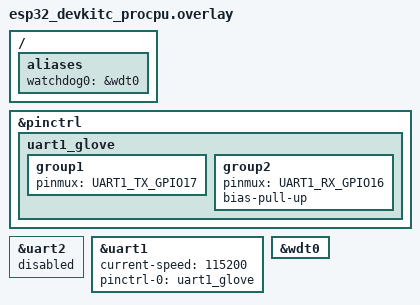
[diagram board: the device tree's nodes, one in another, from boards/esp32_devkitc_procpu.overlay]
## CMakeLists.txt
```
# SPDX-License-Identifier: Apache-2.0
# GloveAssist — ESP32 Application CMakeLists.txt

cmake_minimum_required(VERSION 3.20.0)

find_package(Zephyr REQUIRED HINTS $ENV{ZEPHYR_BASE})
project(gloveassist_esp32 LANGUAGES C)

# Shared + target-specific headers
target_include_directories(app PRIVATE
    ${CMAKE_CURRENT_SOURCE_DIR}/../common/include
    ${CMAKE_CURRENT_SOURCE_DIR}/include
)

# Common shared sources (protocol, CRC)
target_sources(app PRIVATE
    ../common/src/frame_protocol.c
)

# ESP32-specific application sources
target_sources(app PRIVATE
    src/main.c
    src/uart_comm.c
    src/comms_ble.c
    src/sensor_filter.c
    src/gesture_classify.c
)

if(CONFIG_NETWORKING AND CONFIG_MQTT_LIB)
    target_sources(app PRIVATE src/wifi_mqtt.c)
endif()
```

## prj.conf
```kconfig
# GloveAssist — ESP32 Kconfig
# Target: ESP32-WROOM DevKit — BLE gateway + UART receiver

# ---- Kernel ----
CONFIG_MULTITHREADING=y
CONFIG_MAIN_STACK_SIZE=2048
CONFIG_SYSTEM_WORKQUEUE_STACK_SIZE=2048
CONFIG_IDLE_STACK_SIZE=1024
CONFIG_ISR_STACK_SIZE=2048

# ---- GPIO ----
CONFIG_GPIO=y

# ---- UART (inter-MCU communication with STM32 via UART2) ----
CONFIG_UART_INTERRUPT_DRIVEN=y

# ---- Display ----
# OLED is connected to STM32 over I2C2. ESP32 does not drive a display.

# ---- Bluetooth (NUS service) ----
CONFIG_BT=y
CONFIG_BT_PERIPHERAL=y
CONFIG_BT_GATT_DYNAMIC_DB=y
CONFIG_BT_DEVICE_NAME="GloveAssist"
CONFIG_BT_MAX_CONN=1
# Keep the hardware validation image simple: no pairing required for nRF Connect/app tests.
# The encrypted profile can be re-enabled after the end-to-end flow is stable.
CONFIG_BT_SMP=n

# ---- PWM (motor + buzzer, optional on ESP32) — disabled for initial build ----
# CONFIG_PWM=y

# ---- Watchdog ----
CONFIG_WATCHDOG=y

# ---- Logging ----
CONFIG_LOG=y
CONFIG_LOG_DEFAULT_LEVEL=4
CONFIG_LOG_BACKEND_UART=y
CONFIG_LOG_MODE_IMMEDIATE=y

# ---- Safety ----
CONFIG_THREAD_MONITOR=y

# ---- Networking stack (optional cloud profile) ----
CONFIG_NETWORKING=n
CONFIG_WIFI=n
CONFIG_MQTT_LIB=n

# ---- Entropy for protocol security ----
CONFIG_ENTROPY_GENERATOR=y
CONFIG_TEST_RANDOM_GENERATOR=y

# ---- Build options ----
CONFIG_ASSERT=n
CONFIG_SIZE_OPTIMIZATIONS=y
CONFIG_BOOT_BANNER=n
CONFIG_THREAD_NAME=n

# ---- OTA via BLE (MCUboot + SMP) ---- DISABLED for initial hardware validation
# Will re-enable after optimizing RAM usage in Phase 19
CONFIG_BOOTLOADER_MCUBOOT=y
# CONFIG_MCUMGR=y
# CONFIG_MCUMGR_TRANSPORT_BT=y
# CONFIG_MCUMGR_GRP_IMG=y
# CONFIG_MCUMGR_GRP_OS=y
# CONFIG_IMG_MANAGER=y
# CONFIG_STREAM_FLASH=y
# CONFIG_IMG_ERASE_PROGRESSIVELY=y
# CONFIG_IMG_BLOCK_BUF_SIZE=512

# Flash subsystem
CONFIG_FLASH=y
CONFIG_FLASH_MAP=y
CONFIG_FLASH_PAGE_LAYOUT=y

# BLE MTU standard
CONFIG_BT_L2CAP_TX_MTU=65
CONFIG_BT_BUF_ACL_RX_SIZE=69
CONFIG_BT_BUF_ACL_TX_SIZE=69
CONFIG_BT_AUTO_DATA_LEN_UPDATE=n
CONFIG_BT_GAP_AUTO_UPDATE_CONN_PARAMS=n
CONFIG_BT_GATT_CACHING=n
CONFIG_BT_GATT_SERVICE_CHANGED=n
CONFIG_BT_RX_STACK_SIZE=2048
CONFIG_BT_HCI_TX_STACK_SIZE=2048
CONFIG_BT_TX_PROCESSOR_STACK_SIZE=1536
CONFIG_BT_LONG_WQ_STACK_SIZE=2048
CONFIG_LOG_PROCESS_THREAD_STACK_SIZE=1536

# Heap sized for BLE + UART + security diagnostics
CONFIG_HEAP_MEM_POOL_SIZE=8192

# Additional RAM optimizations
CONFIG_BT_ATT_PREPARE_COUNT=2
CONFIG_SYSTEM_WORKQUEUE_NO_YIELD=y
```

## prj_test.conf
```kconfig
# HARDWARE TEST CONFIG - Minimal BLE + UART
# Quick validation for soldering and hardware connections

# === Kernel basics ===
CONFIG_MAIN_STACK_SIZE=1024
CONFIG_IDLE_STACK_SIZE=512
CONFIG_ISR_STACK_SIZE=1536
CONFIG_SYSTEM_WORKQUEUE_STACK_SIZE=1024

# === GPIO + UART ===
CONFIG_GPIO=y
CONFIG_SERIAL=y
CONFIG_UART_INTERRUPT_DRIVEN=y
CONFIG_CONSOLE=y
CONFIG_UART_CONSOLE=y

# === BLE Peripheral (minimal) ===
CONFIG_BT=y
CONFIG_BT_PERIPHERAL=y
CONFIG_BT_DEVICE_NAME="GloveTest"
CONFIG_BT_DEVICE_NAME_MAX=16
CONFIG_BT_MAX_CONN=1

# BLE NUS service for testing
CONFIG_BT_NUS=y
CONFIG_BT_NUS_THREAD_STACK_SIZE=1024
CONFIG_BT_NUS_UART_BUFFER_SIZE=64

# BLE stack minimal
CONFIG_BT_L2CAP_TX_MTU=100
CONFIG_BT_BUF_ACL_TX_SIZE=100
CONFIG_BT_BUF_ACL_RX_SIZE=100
CONFIG_BT_CTLR_TX_BUFFERS=3
CONFIG_BT_CTLR_RX_BUFFERS=3

# === Logging (verbose for debugging) ===
CONFIG_LOG=y
CONFIG_LOG_DEFAULT_LEVEL=3
CONFIG_LOG_MODE_DEFERRED=y
CONFIG_LOG_BUFFER_SIZE=512
CONFIG_PRINTK=y

# === Safety ===
CONFIG_WATCHDOG=y
CONFIG_WDT_DISABLE_AT_BOOT=y

# === Memory optimization ===
CONFIG_HEAP_MEM_POOL_SIZE=8192
CONFIG_SIZE_OPTIMIZATIONS=y

# === Thread monitoring ===
CONFIG_THREAD_NAME=y
CONFIG_THREAD_MONITOR=y
```

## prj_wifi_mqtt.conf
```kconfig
# Optional profile: enable WiFi + MQTT/TLS cloud gateway on ESP32
# Use with: west build ... -- -DEXTRA_CONF_FILE=prj_wifi_mqtt.conf

CONFIG_NETWORKING=y
CONFIG_NET_IPV4=y
CONFIG_NET_IPV6=n
CONFIG_NET_TCP=y
CONFIG_NET_SOCKETS=y
CONFIG_NET_DHCPV4=y
CONFIG_NET_MGMT=y
CONFIG_NET_MGMT_EVENT=y
CONFIG_NET_MGMT_EVENT_INFO=y
CONFIG_WIFI=y
CONFIG_NET_L2_ETHERNET=y

CONFIG_MQTT_LIB=y
CONFIG_MQTT_LIB_TLS=y
CONFIG_NET_SOCKETS_SOCKOPT_TLS=y
CONFIG_TLS_CREDENTIALS=y

CONFIG_MBEDTLS=y
CONFIG_MBEDTLS_ENABLE_HEAP=y
CONFIG_MBEDTLS_HEAP_SIZE=6144
CONFIG_MBEDTLS_SSL_MAX_CONTENT_LEN=2048
CONFIG_MBEDTLS_PEM_PARSE_C=y
CONFIG_MBEDTLS_X509_CRT_PARSE_C=y
CONFIG_MBEDTLS_CIPHERSUITE_TLS_ECDHE_RSA_WITH_AES_128_GCM_SHA256=y
CONFIG_MBEDTLS_SSL_SERVER_NAME_INDICATION=y

CONFIG_DNS_RESOLVER=y
CONFIG_NET_PKT_RX_COUNT=6
CONFIG_NET_PKT_TX_COUNT=6
CONFIG_NET_BUF_RX_COUNT=12
CONFIG_NET_BUF_TX_COUNT=12
CONFIG_NET_BUF_DATA_SIZE=128
CONFIG_NET_MAX_CONTEXTS=6
CONFIG_NET_TX_STACK_SIZE=1152
CONFIG_NET_RX_STACK_SIZE=1152

CONFIG_HEAP_MEM_POOL_SIZE=15360
CONFIG_ESP32_TIMER_TASK_STACK_SIZE=1408
CONFIG_MQTT_KEEPALIVE=60

# ---- ESP32-WROOM memory profile for BLE + WiFi + MQTT/TLS together ----
# This project sends short BLE notifications and tiny MQTT payloads, so we can
# trade throughput for RAM headroom.
CONFIG_HEAP_MEM_POOL_IGNORE_MIN=y
CONFIG_HEAP_MEM_POOL_SIZE=45056

CONFIG_BT_L2CAP_TX_MTU=69
CONFIG_BT_BUF_ACL_RX_SIZE=73
CONFIG_BT_BUF_ACL_TX_SIZE=73
CONFIG_BT_BUF_ACL_TX_COUNT=3
CONFIG_BT_L2CAP_TX_BUF_COUNT=3
CONFIG_BT_L2CAP_TX_FRAG_COUNT=1
CONFIG_BT_ATT_PREPARE_COUNT=1
CONFIG_ESP32_BT_CTLR_LE_MAX_CONN=1
CONFIG_ESP32_BT_CTLR_LE_MAX_ACT=2
CONFIG_ESP32_BT_CTLR_ADV_DUP_FILT_MAX=5

CONFIG_ESP32_WIFI_STATIC_RX_BUFFER_NUM=4
CONFIG_ESP32_WIFI_DYNAMIC_RX_BUFFER_NUM=8
CONFIG_ESP32_WIFI_DYNAMIC_TX_BUFFER_NUM=8
CONFIG_ESP32_WIFI_RX_MGMT_BUF_NUM_DEF=2
CONFIG_ESP32_WIFI_MGMT_SBUF_NUM=8
CONFIG_ESP32_WIFI_AMPDU_TX_ENABLED=n
CONFIG_ESP32_WIFI_AMPDU_RX_ENABLED=n
```

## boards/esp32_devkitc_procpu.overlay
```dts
/*
 * Board overlay for ESP32-WROOM (30-pin DevKit) — GloveAssist ESP32 app
 *
 * UART2:       STM32 inter-MCU communication
 *     GPIO17 TX  (→ STM32 PA10 RX)
 *     GPIO16 RX  (← STM32 PA9  TX)
 * BLE:  Handled by Zephyr BT subsystem
 * WDT:  Task watchdog (wdt0)
 *
 * Flash partition layout for MCUboot OTA (4MB ESP32-WROOM flash):
 *   0x000000 - 0x00FFFF  mcuboot bootloader   (64 KB, read-only)
 *   0x010000 - 0x0FFFFF  image-0 (slot0)      (960 KB, primary running image)
 *   0x100000 - 0x1EFFFF  image-1 (slot1)      (960 KB, OTA update staging area)
 *   0x1F0000 - 0x1FFFFF  image-scratch        (64 KB, MCUboot swap scratch)
 *   0x3F0000 - 0x3FFFFF  storage              (64 KB, NVS / calib data)
 */

/ {
	aliases {
		watchdog0 = &wdt0;
	};
};

&pinctrl {
	uart1_glove: uart1_glove {
		group1 {
			pinmux = <UART1_TX_GPIO17>;
		};

		group2 {
			pinmux = <UART1_RX_GPIO16>;
			bias-pull-up;
		};
	};
};

/* ---- UART2: STM32 inter-MCU communication ---- */
/* GPIO17=TX, GPIO16=RX  (uart2_default, 115200 baud, 8N1 prototype mode) */
&uart2 {
	status = "disabled";
};

&uart1 {
	status = "okay";
	current-speed = <115200>;
	pinctrl-0 = <&uart1_glove>;
	pinctrl-names = "default";
};

/* ---- Watchdog ---- */
&wdt0 {
	status = "okay";
};

/*
 * Flash partitions: Using Zephyr default layout (no MCUboot, no custom partitions)
 * ESP32 ROM bootloader + Zephyr will manage:
 *   - 2nd stage bootloader at 0x1000
 *   - Partition table at 0x8000  
 *   - Application at 0x10000
 * Board default includes storage partition already
 */
```

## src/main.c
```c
/**
 * @file main.c
 * @brief GloveAssist ESP32 firmware — BRAIN (v2.0 Architecture)
 *
 * ESP32 responsibilities (NEW ARCH):
 *   - UART2 RX: receive RAW ADC frames from STM32 (sensor hub)
 *   - Filtering: Apply moving average filter
 *   - Classification: Detect gestures from filtered data
 *   - UART2 TX: send GESTURE frames back to STM32 for haptic feedback
 *   - BLE NUS: forward gestures to phone, relay commands to STM32
 *   - WiFi/MQTT: publish gestures to Adafruit IO dashboard
 *   - Calibration: Handle all calibration logic, store thresholds in ESP32 NVS
 */

#include <zephyr/kernel.h>
#include <zephyr/logging/log.h>
#if defined(CONFIG_BOOTLOADER_MCUBOOT) && defined(CONFIG_MCUBOOT_IMG_MANAGER)
#include <zephyr/dfu/mcuboot.h>
#endif

#include "app_config.h"
#include "common_types.h"
#include "frame_protocol.h"
#include "comms_ble.h"
#include "uart_comm.h"
#include "wifi_mqtt.h"
#include "sensor_filter.h"
#include "gesture_classify.h"

LOG_MODULE_REGISTER(main, CONFIG_LOG_DEFAULT_LEVEL);

/* ---------- Thread definitions ---------- */
K_THREAD_DEFINE(uart_comm_tid, STACK_UART_COMM,
                uart_comm_thread_entry, NULL, NULL, NULL,
                PRIO_UART_COMM_THREAD, 0, 0);

#if defined(CONFIG_NETWORKING) && defined(CONFIG_MQTT_LIB)
K_THREAD_DEFINE(wifi_mqtt_tid, STACK_WIFI_MQTT,
                wifi_mqtt_thread_entry, NULL, NULL, NULL,
                PRIO_WIFI_MQTT_THREAD, 0, 0);
#endif

/* ---------- Message queue: UART RX gestures → BLE TX ---------- */
K_MSGQ_DEFINE(ble_tx_msgq, sizeof(sensor_packet_t), 8, 4);

int main(void)
{
    LOG_INF("=== GloveAssist ESP32 Brain (v2.0) ===");
#if defined(CONFIG_NETWORKING) && defined(CONFIG_MQTT_LIB)
    LOG_INF("Threads: uart_comm(P%d) wifi_mqtt(P%d)",
            PRIO_UART_COMM_THREAD, PRIO_WIFI_MQTT_THREAD);
#else
    LOG_INF("Threads: uart_comm(P%d), WiFi/MQTT disabled for BLE test",
            PRIO_UART_COMM_THREAD);
#endif

    /* Initialize processing modules (NEW v2.0) */
    int ret = sensor_filter_init();
    if (ret < 0) {
        LOG_ERR("sensor_filter_init failed: %d", ret);
    }

    ret = gesture_classify_init();
    if (ret < 0) {
        LOG_ERR("gesture_classify_init failed: %d", ret);
    }

    ret = ble_init();
    if (ret < 0) {
        LOG_ERR("BLE init failed: %d", ret);
    }

    /*
     * Confirm this image as valid so MCUboot does not revert to the
     * previous firmware on the next reboot (revert mode safety feature).
     * Must be called after all critical subsystems are up.
     * If the device resets before reaching this line, MCUboot will
     * automatically restore the previous known-good image.
     */
#if defined(CONFIG_BOOTLOADER_MCUBOOT) && defined(CONFIG_MCUBOOT_IMG_MANAGER)
    ret = boot_write_img_confirmed();
    if (ret < 0) {
        LOG_WRN("MCUboot image confirm failed: %d (first boot?)", ret);
    } else {
        LOG_INF("MCUboot image confirmed as valid");
    }
#endif

    LOG_INF("ESP32 Brain initialized — processing pipeline ready");
    LOG_INF("All threads auto-started — main() returning to idle");
    return 0;
}
```

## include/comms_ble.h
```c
/**
 * @file comms_ble.h
 * @brief BLE NUS (Nordic UART Service) gateway API (ESP32)
 */

#ifndef COMMS_BLE_H
#define COMMS_BLE_H

#include <stdint.h>
#include <stdbool.h>

/**
 * @brief Initialise and start BLE advertising (NUS service).
 * @return 0 on success, negative Zephyr error code on failure.
 */
int ble_init(void);

/**
 * @brief Send a GATT notification to the connected BLE central.
 *
 * @param data  Payload buffer.
 * @param len   Number of bytes to send.
 * @return 0 on success, negative on error or if no central is connected.
 */
int ble_send_notification(const uint8_t *data, uint16_t len);

/**
 * @brief Check if a BLE central is currently connected.
 * @return true if connected.
 */
bool ble_is_connected(void);

/**
 * @brief Get last RSSI reading (dBm, 0 if not available).
 * @return RSSI as signed byte magnitude stored in uint8_t.
 */
uint8_t ble_get_rssi(void);

/**
 * @brief Format 4 raw 12-bit ADC values as text and send via BLE NUS notify.
 *
 * Sends a string like: "I:1234 M:2048 R:3012 P:0512\n"
 * Use nRF Connect or Serial Bluetooth Terminal on the phone to read values.
 *
 * @param raw  Array of 4 uint16_t: [index, middle, ring, pinky]
 * @return 0 on success, negative if not connected or notify disabled.
 */
int ble_send_raw_adc_text(const uint16_t raw[4]);

#endif /* COMMS_BLE_H */
```

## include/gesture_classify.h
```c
/**
 * @file gesture_classify.h
 * @brief Gesture classification engine (ESP32 brain)
 * 
 * Takes filtered sensor values, applies threshold-based rules
 * to detect gestures.
 * 
 * NEW ARCHITECTURE (v2.0):
 * - STM32: Dumb sensor hub
 * - ESP32: Smart classification → sends MSG_TYPE_GESTURE to STM32
 */

#ifndef GESTURE_CLASSIFY_H
#define GESTURE_CLASSIFY_H

#include <stdint.h>
#include <stdbool.h>
#include "common_types.h"

/**
 * @brief Initialize gesture classifier
 * 
 * Loads thresholds from NVS (ESP32-local storage).
 * 
 * @return 0 on success, negative on error
 */
int gesture_classify_init(void);

/**
 * @brief Classify gesture from filtered sensor values
 * 
 * @param filtered Array of NUM_FLEX_SENSORS filtered ADC values
 * @return Gesture ID (GESTURE_NONE, GESTURE_FIST, etc.)
 */
uint8_t gesture_classify(const uint16_t filtered[NUM_FLEX_SENSORS]);

/**
 * @brief Update thresholds (e.g., after calibration)
 * 
 * @param thresh Array of NUM_FLEX_SENSORS threshold values
 * @return 0 on success, negative on error
 */
int gesture_classify_update_thresholds(const uint16_t thresh[NUM_FLEX_SENSORS]);

/**
 * @brief Get current threshold for a finger
 * 
 * @param finger Finger index (FINGER_INDEX, etc.)
 * @return Threshold value, or 0 if invalid
 */
uint16_t gesture_classify_get_threshold(uint8_t finger);

/**
 * @brief Get all thresholds at once
 * 
 * @param out Output array of NUM_FLEX_SENSORS elements
 */
void gesture_classify_get_all_thresholds(uint16_t out[NUM_FLEX_SENSORS]);

#endif /* GESTURE_CLASSIFY_H */
```

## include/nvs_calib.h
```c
// nvs_calib.h
// Header for NVS calibration storage for gesture thresholds

#ifndef NVS_CALIB_H
#define NVS_CALIB_H

#include <stdint.h>
#include <stdbool.h>

#define NUM_FLEX_SENSORS 4

// Struct for storing calibration values (e.g., FIST reference)
typedef struct {
    uint16_t fist_adc[NUM_FLEX_SENSORS];
    uint32_t crc;
} nvs_calib_data_t;

// Save calibration data to NVS
bool nvs_calib_save(const nvs_calib_data_t *data);

// Load calibration data from NVS (returns true if valid)
bool nvs_calib_load(nvs_calib_data_t *data);

// Check if calibration is present in NVS
bool nvs_calib_exists(void);

#endif // NVS_CALIB_H
```

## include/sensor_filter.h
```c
/**
 * @file sensor_filter.h
 * @brief Moving average filter for flex sensor data (ESP32 brain)
 * 
 * Receives raw 12-bit ADC values from STM32 via UART, applies
 * moving average filter, provides filtered values for gesture classification.
 * 
 * NEW ARCHITECTURE (v2.0):
 * - STM32: ADC acquisition only → sends MSG_TYPE_RAW_ADC
 * - ESP32: Filtering, classification, calibration → sends MSG_TYPE_GESTURE
 */

#ifndef SENSOR_FILTER_H
#define SENSOR_FILTER_H

#include <stdint.h>
#include <stdbool.h>
#include "common_types.h"

/**
 * @brief Initialize filter subsystem
 * 
 * Allocates buffers, resets state.
 * 
 * @return 0 on success, negative on error
 */
int sensor_filter_init(void);

/**
 * @brief Update filter with new raw ADC sample
 * 
 * @param channel Channel index (0-3)
 * @param raw_value Raw 12-bit ADC value (0-4095)
 * @return Filtered value (moving average)
 */
uint16_t sensor_filter_update(uint8_t channel, uint16_t raw_value);

/**
 * @brief Get current filtered value for a channel
 * 
 * @param channel Channel index (0-3)
 * @return Filtered value, or 0 if channel invalid
 */
uint16_t sensor_filter_get(uint8_t channel);

/**
 * @brief Get all filtered values at once
 * 
 * @param out Output array of NUM_FLEX_SENSORS elements
 */
void sensor_filter_get_all(uint16_t out[NUM_FLEX_SENSORS]);

/**
 * @brief Reset filter state (e.g., on calibration start)
 */
void sensor_filter_reset(void);

/**
 * @brief Get filter window size
 * 
 * @return Number of samples in moving average window
 */
uint8_t sensor_filter_get_window_size(void);

#endif /* SENSOR_FILTER_H */
```

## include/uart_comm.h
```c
/**
 * @file uart_comm.h
 * @brief UART inter-MCU communication thread API (ESP32 side)
 *
 * ESP32 receives frames from STM32 via UART2 (GPIO16 RX, GPIO17 TX).
 * Protocol: glove_frame_t, 12 bytes — SOF + TYPE + SEQ + PAYLOAD[8] XOR + CRC8.
 */

#ifndef UART_COMM_ESP32_H
#define UART_COMM_ESP32_H

#include <stdint.h>
#include "frame_protocol.h"

/**
 * @brief UART RX thread entry point (auto-started via K_THREAD_DEFINE).
 *
 * Receives complete frames from STM32, validates CRC, dispatches payloads
 * to the BLE TX queue. Sends heartbeat responses asynchronously.
 */
void uart_comm_thread_entry(void *p1, void *p2, void *p3);

/**
 * @brief Send a frame to STM32 via UART (called from any thread/timer).
 *
 * @param frame  Pointer to the frame to transmit.
 * @return 0 on success, negative errno on failure.
 */
int uart_comm_send(const glove_frame_t *frame);

/**
 * @brief Impacheteaza o comanda BLE intr-un frame UART si o trimite la STM32.
 *
 * Apelat din comms_ble.c::on_rx_write() cand telefonul trimite o comanda.
 * Construieste frame MSG_TYPE_COMMAND, aplica XOR+CRC, transmite pe UART.
 *
 * @param cmd  Pointer la structura comanda deja populata.
 * @return 0 la succes, negativ la eroare.
 */
int uart_comm_send_command(const frame_command_payload_t *cmd);

/**
 * @brief Send a compact sniff/security diagnostics report over BLE.
 *
 * This report summarizes UART traffic health (CRC drops, replay drops,
 * honeypot count, lockdown state) and is used for anti-sniffing validation.
 *
 * @return 0 on success, negative errno on failure.
 */
int uart_comm_send_sniff_report(void);

#endif /* UART_COMM_ESP32_H */
```

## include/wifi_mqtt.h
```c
/**
 * @file wifi_mqtt.h
 * @brief WiFi connection + Adafruit IO MQTT publishing (ESP32)
 *
 * Architecture:
 *   wifi_mqtt_thread — connects to WiFi, then to MQTT broker,
 *                      publishes gesture/status from a msgq.
 *
 * Publishing from other threads:
 *   wifi_mqtt_publish_gesture(id, confidence) — non-blocking enqueue
 *   wifi_mqtt_publish_status(alive, ble_conn) — non-blocking enqueue
 */

#ifndef WIFI_MQTT_H
#define WIFI_MQTT_H

#include <stdint.h>
#include <stdbool.h>

/**
 * @brief WiFi + MQTT background thread entry (K_THREAD_DEFINE).
 */
void wifi_mqtt_thread_entry(void *p1, void *p2, void *p3);

/**
 * @brief Enqueue a gesture event for MQTT publishing.
 *
 * @param gesture_id   Gesture identifier (GESTURE_* from app_config.h).
 * @param confidence   Detection confidence 0-100.
 * @return 0 on success, -EAGAIN if queue full (dropped).
 */
int wifi_mqtt_publish_gesture(uint8_t gesture_id, uint8_t confidence);

/**
 * @brief Enqueue a status update for MQTT publishing.
 *
 * @param esp32_alive  Always true when called from ESP32.
 * @param ble_conn     True if BLE central is connected.
 */
int wifi_mqtt_publish_status(bool esp32_alive, bool ble_conn);

/**
 * @brief Returns true if WiFi is connected and MQTT broker is reachable.
 */
bool wifi_mqtt_is_connected(void);

#endif /* WIFI_MQTT_H */
```

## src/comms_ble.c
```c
/**
 * @file comms_ble.c
 * @brief BLE NUS (Nordic UART Service) gateway on ESP32
 *
 * Receives gesture/sensor data from STM32 via UART, forwards to
 * connected BLE Central as GATT notifications.
 * Also sends commands from BLE Central back to STM32 via UART.
 */

#include <zephyr/kernel.h>
#include <zephyr/bluetooth/bluetooth.h>
#include <zephyr/bluetooth/gatt.h>
#include <zephyr/bluetooth/uuid.h>
#include <zephyr/bluetooth/conn.h>
#include <zephyr/bluetooth/hci.h>
#include <zephyr/logging/log.h>
#include <stdio.h>
#include <string.h>

#include "app_config.h"
#include "common_types.h"
#include "frame_protocol.h"
#include "uart_comm.h"
#include "comms_ble.h"

LOG_MODULE_REGISTER(comms_ble, CONFIG_LOG_DEFAULT_LEVEL);

/* ---------- NUS UUIDs ---------- */
static struct bt_uuid_128 nus_svc_uuid = BT_UUID_INIT_128(
    BT_UUID_128_ENCODE(0x6e400001, 0xb5a3, 0xf393, 0xe0a9, 0xe50e24dcca9e));

static struct bt_uuid_128 nus_tx_uuid = BT_UUID_INIT_128(
    BT_UUID_128_ENCODE(0x6e400003, 0xb5a3, 0xf393, 0xe0a9, 0xe50e24dcca9e));

static struct bt_uuid_128 nus_rx_uuid = BT_UUID_INIT_128(
    BT_UUID_128_ENCODE(0x6e400002, 0xb5a3, 0xf393, 0xe0a9, 0xe50e24dcca9e));

/* ---------- Connection state ---------- */
static struct bt_conn *current_conn;
static bool ble_notif_enabled;

/* ---------- GATT callbacks ---------- */
static void ccc_changed(const struct bt_gatt_attr *attr, uint16_t value)
{
    ble_notif_enabled = (value == BT_GATT_CCC_NOTIFY);
    LOG_INF("BLE notifications %s", ble_notif_enabled ? "enabled" : "disabled");
}

static ssize_t on_rx_write(struct bt_conn *conn,
                           const struct bt_gatt_attr *attr,
                           const void *buf, uint16_t len,
                           uint16_t offset, uint8_t flags)
{
    ARG_UNUSED(attr);
    ARG_UNUSED(offset);
    ARG_UNUSED(flags);

    if (len > PROTO_PAYLOAD_SIZE) {
        LOG_WRN("BLE RX: payload too large (%u)", len);
        return BT_GATT_ERR(BT_ATT_ERR_INVALID_ATTRIBUTE_LEN);
    }

    /* Minimum 1 byte: cmd_id */
    if (len < 1U) {
        LOG_WRN("BLE RX: payload gol — ignorat");
        return BT_GATT_ERR(BT_ATT_ERR_INVALID_ATTRIBUTE_LEN);
    }

    LOG_INF("BLE RX: %u bytes de la central", len);

    /* Text shortcut: phone sends ASCII "inteles\n" or "inteles" →
     * auto-map to CMD_ACK_RECEIVED for user-friendly app integration */
    {
        const uint8_t *text = (const uint8_t *)buf;
        bool is_ack_text = false;

        if ((len >= 7U) && (memcmp(text, "inteles", 7U) == 0)) {
            is_ack_text = true;
        } else if ((len >= 3U) && (memcmp(text, "ack", 3U) == 0)) {
            is_ack_text = true;
        } else if ((len >= 2U) && (memcmp(text, "ok", 2U) == 0)) {
            is_ack_text = true;
        }

        if (is_ack_text) {
            frame_command_payload_t ack_cmd;
            (void)memset(&ack_cmd, 0, sizeof(ack_cmd));
            ack_cmd.cmd_id = CMD_ACK_RECEIVED;
            int ack_rc = uart_comm_send_command(&ack_cmd);
            if (ack_rc < 0) {
                LOG_ERR("CMD_ACK_RECEIVED relay failed: %d", ack_rc);
                return BT_GATT_ERR(BT_ATT_ERR_UNLIKELY);
            }
            {
                const char ack_ok[] = "OK:ACK relayed\n";
                (void)ble_send_notification((const uint8_t *)ack_ok,
                                            (uint16_t)(sizeof(ack_ok) - 1U));
            }
            LOG_INF("BLE text ACK -> CMD_ACK_RECEIVED relayed to STM32");
            return (ssize_t)len;
        }
    }

    /* Populeaza structura comanda din bytes primiti de la telefon.
     * Format asteptat: [cmd_id 1B][finger_idx 1B][value_lo 1B][value_hi 1B]
     * Bytes lipsa → raman 0 (zero-init prin memset). */
    frame_command_payload_t cmd;
    (void)memset(&cmd, 0, sizeof(cmd));

    const uint8_t *data = (const uint8_t *)buf;
    cmd.cmd_id = data[0];
    if (len >= 2U) {
        cmd.finger_idx = data[1];
    }
    if (len >= 4U) {
        /* value little-endian: [value_lo, value_hi] */
        cmd.value = (uint16_t)((uint16_t)data[2] | ((uint16_t)data[3] << 8U));
    }

    if (cmd.cmd_id == CMD_SNIFF_REPORT) {
        int local_rc = uart_comm_send_sniff_report();
        if (local_rc < 0) {
            LOG_ERR("SNIFF report send failed: %d", local_rc);
            return BT_GATT_ERR(BT_ATT_ERR_UNLIKELY);
        }
        LOG_INF("SNIFF report sent to BLE central");
        return (ssize_t)len;
    }

    int rc = uart_comm_send_command(&cmd);
    if (rc < 0) {
        LOG_ERR("Relay comanda la STM32 esuat: %d", rc);
        return BT_GATT_ERR(BT_ATT_ERR_UNLIKELY);
    }

    return (ssize_t)len;
}

/* ---------- GATT service definition ---------- */
BT_GATT_SERVICE_DEFINE(nus_svc,
    BT_GATT_PRIMARY_SERVICE(&nus_svc_uuid),

    /* TX characteristic (notify: ESP32 -> Phone) */
    BT_GATT_CHARACTERISTIC(&nus_tx_uuid.uuid,
                           BT_GATT_CHRC_NOTIFY,
                           BT_GATT_PERM_NONE,
                           NULL, NULL, NULL),
    BT_GATT_CCC(ccc_changed, BT_GATT_PERM_READ | BT_GATT_PERM_WRITE),

    /* RX characteristic (write: Phone -> ESP32) */
    BT_GATT_CHARACTERISTIC(&nus_rx_uuid.uuid,
                           BT_GATT_CHRC_WRITE | BT_GATT_CHRC_WRITE_WITHOUT_RESP,
                           BT_GATT_PERM_WRITE,
                           NULL, on_rx_write, NULL),
);

/* ---------- Connection callbacks ---------- */
static void connected(struct bt_conn *conn, uint8_t err)
{
    if (err) {
        LOG_ERR("BLE connection failed: 0x%02x", err);
        return;
    }

    current_conn = bt_conn_ref(conn);
    LOG_INF("BLE connected");
}

static void disconnected(struct bt_conn *conn, uint8_t reason)
{
    LOG_INF("BLE disconnected (reason 0x%02x)", reason);
    if (current_conn) {
        bt_conn_unref(current_conn);
        current_conn = NULL;
    }
    ble_notif_enabled = false;
}

BT_CONN_CB_DEFINE(conn_cb) = {
    .connected    = connected,
    .disconnected = disconnected,
};

/* ---------- Advertising data (defined before SMP callbacks that reference them) ---------- */
static const struct bt_data ad[] = {
    BT_DATA_BYTES(BT_DATA_FLAGS, (BT_LE_AD_GENERAL | BT_LE_AD_NO_BREDR)),
    BT_DATA(BT_DATA_NAME_COMPLETE, "GloveAssist", sizeof("GloveAssist") - 1),
};

static const struct bt_data sd[] = {
    BT_DATA_BYTES(BT_DATA_UUID128_ALL,
        BT_UUID_128_ENCODE(0x6e400001, 0xb5a3, 0xf393, 0xe0a9, 0xe50e24dcca9e)),
};

static const struct bt_le_adv_param *const adv_params =
    BT_LE_ADV_PARAM(BT_LE_ADV_OPT_CONN,
                    BT_GAP_ADV_FAST_INT_MIN_2,
                    BT_GAP_ADV_FAST_INT_MAX_2,
                    NULL);

#if defined(CONFIG_BT_SMP)
/* ---------- SMP pairing callbacks ---------- */
static void auth_cancel(struct bt_conn *conn)
{
    LOG_WRN("BLE pairing cancelled");
    ARG_UNUSED(conn);
}

static void auth_passkey_display(struct bt_conn *conn, unsigned int passkey)
{
    ARG_UNUSED(conn);
    LOG_INF("BLE pairing passkey: %06u", passkey);
}

static void pairing_complete(struct bt_conn *conn, bool bonded)
{
    LOG_INF("BLE pairing complete (bonded=%d)", bonded);
    ARG_UNUSED(conn);
}

static void pairing_failed(struct bt_conn *conn,
                            enum bt_security_err reason)
{
    LOG_WRN("BLE pairing failed (reason %d) — will retry", reason);
    ARG_UNUSED(conn);
    /* Re-advertise after pairing failure */
    (void)bt_le_adv_start(adv_params, ad, ARRAY_SIZE(ad),
                          sd, ARRAY_SIZE(sd));
}

static struct bt_conn_auth_cb auth_cb = {
    .passkey_display = auth_passkey_display,
    .cancel          = auth_cancel,
};

static struct bt_conn_auth_info_cb auth_info_cb = {
    .pairing_complete = pairing_complete,
    .pairing_failed   = pairing_failed,
};
#endif

/* ---------- Public API ---------- */

int ble_init(void)
{
    int err = bt_enable(NULL);
    if (err) {
        LOG_ERR("bt_enable failed: %d", err);
        return err;
    }

    LOG_INF("BLE initialised");

#if defined(CONFIG_BT_SMP)
    /* Register SMP (Just Works pairing) */
    err = bt_conn_auth_cb_register(&auth_cb);
    if (err) {
        LOG_WRN("auth_cb register failed: %d", err);
    }
    err = bt_conn_auth_info_cb_register(&auth_info_cb);
    if (err) {
        LOG_WRN("auth_info_cb register failed: %d", err);
    }
#endif

    err = bt_le_adv_start(adv_params, ad, ARRAY_SIZE(ad),
                          sd, ARRAY_SIZE(sd));
    if (err) {
        LOG_ERR("Advertising start failed: %d", err);
        return err;
    }

    LOG_INF("BLE advertising as 'GloveAssist'");
    return 0;
}

int ble_send_notification(const uint8_t *data, uint16_t len)
{
    int32_t result;

    if (!current_conn || !ble_notif_enabled) {
        result = -ENOTCONN;
    } else {
        struct bt_gatt_notify_params params = {
            .uuid = &nus_tx_uuid.uuid,
            .attr = &nus_svc.attrs[1],
            .data = data,
            .len  = len,
        };
        result = bt_gatt_notify_cb(current_conn, &params);
    }

    return result;
}

bool ble_is_connected(void)
{
    return (current_conn != NULL);
}

uint8_t ble_get_rssi(void)
{
    /* RSSI reading requires bt_conn_get_info — simplified stub for Phase 2 */
    return 0U;
}

int ble_send_raw_adc_text(const uint16_t raw[4])
{
    /* Format: "I:1234 M:2048 R:3012 P:0512\n" (max 29 chars, fits in BLE MTU) */
    char    buf[32];
    int     n;

    n = snprintf(buf, sizeof(buf), "I:%04u M:%04u R:%04u P:%04u\n",
                 (unsigned int)raw[0], (unsigned int)raw[1],
                 (unsigned int)raw[2], (unsigned int)raw[3]);

    if (n <= 0) {
        return -EINVAL;
    }

    return ble_send_notification((const uint8_t *)buf, (uint16_t)n);
}
```

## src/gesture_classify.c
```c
/**
 * @file gesture_classify.c
 * @brief Gesture classification engine (ESP32 brain)
 */

#include <zephyr/kernel.h>
#include <zephyr/logging/log.h>
#include <string.h>

#include "app_config.h"
#include "common_types.h"
#include "gesture_classify.h"

LOG_MODULE_REGISTER(gesture_classify, CONFIG_LOG_DEFAULT_LEVEL);

/* ---------- Thresholds (loaded from NVS or defaults) ---------- */
static uint16_t k_thresh[NUM_FLEX_SENSORS];
static bool initialized = false;

/* Default thresholds (from original STM32 calibration data) */
static const uint16_t k_defaults[NUM_FLEX_SENSORS] = {
    621U,   /* FINGER_INDEX  */
    874U,   /* FINGER_MIDDLE */
    2009U,  /* FINGER_RING   */
    944U,   /* FINGER_PINKY  */
};

int gesture_classify_init(void)
{
    if (initialized) {
        LOG_WRN("gesture_classify already initialized");
        return 0;
    }

    /* TODO: Load thresholds from ESP32 NVS */
    /* For now, use defaults */
    (void)memcpy(k_thresh, k_defaults, sizeof(k_thresh));

    initialized = true;
    LOG_INF("Gesture classifier initialized");
    LOG_INF("Thresholds: I=%u M=%u R=%u P=%u",
            k_thresh[FINGER_INDEX], k_thresh[FINGER_MIDDLE],
            k_thresh[FINGER_RING], k_thresh[FINGER_PINKY]);
    return 0;
}

uint8_t gesture_classify(const uint16_t filtered[NUM_FLEX_SENSORS])
{
    if (!initialized || filtered == NULL) {
        return GESTURE_NONE;
    }

    uint8_t bent_count = 0U;
    uint8_t single_idx = 0U;
    bool bent[NUM_FLEX_SENSORS];

    /* 
     * Circuit: 3.3V → [1kΩ] → PA_x → [flex sensor] → GND
     * Bent sensor: lower resistance → higher voltage → higher ADC
     * BUT: we have pull-down resistors → bent = LOWER ADC value
     * 
     * Rule: ADC < threshold → finger bent
     */
    for (uint8_t i = 0U; i < (uint8_t)NUM_FLEX_SENSORS; i++) {
        bent[i] = (filtered[i] < k_thresh[i]);
        if (bent[i]) {
            single_idx = i;
            bent_count++;
        }
    }

    /* All fingers bent → FIST */
    if (bent_count == (uint8_t)NUM_FLEX_SENSORS) {
        return GESTURE_FIST;
    }

    /* Only one finger bent → specific gesture */
    if (bent_count == 1U) {
        return (uint8_t)(GESTURE_INDEX + single_idx);
    }

    /* Ring + Pinky bent, Index + Middle open → HELP */
    if ((bent_count == 2U) &&
        bent[FINGER_RING] && bent[FINGER_PINKY] &&
        !bent[FINGER_INDEX] && !bent[FINGER_MIDDLE]) {
        return GESTURE_HELP;
    }

    /* No gesture detected */
    return GESTURE_NONE;
}

int gesture_classify_update_thresholds(const uint16_t thresh[NUM_FLEX_SENSORS])
{
    if (!initialized || thresh == NULL) {
        return -EINVAL;
    }

    /* Validate thresholds */
    for (uint8_t i = 0U; i < (uint8_t)NUM_FLEX_SENSORS; i++) {
        if (thresh[i] < (uint16_t)ADC_MIN_VALID ||
            thresh[i] > (uint16_t)ADC_MAX_VALID) {
            LOG_ERR("Invalid threshold for finger %u: %u", i, thresh[i]);
            return -EINVAL;
        }
    }

    (void)memcpy(k_thresh, thresh, sizeof(k_thresh));

    LOG_INF("Thresholds updated: I=%u M=%u R=%u P=%u",
            k_thresh[FINGER_INDEX], k_thresh[FINGER_MIDDLE],
            k_thresh[FINGER_RING], k_thresh[FINGER_PINKY]);

    /* TODO: Save to ESP32 NVS */

    return 0;
}

uint16_t gesture_classify_get_threshold(uint8_t finger)
{
    if (!initialized || finger >= (uint8_t)NUM_FLEX_SENSORS) {
        return 0U;
    }

    return k_thresh[finger];
}

void gesture_classify_get_all_thresholds(uint16_t out[NUM_FLEX_SENSORS])
{
    if (!initialized || out == NULL) {
        return;
    }

    (void)memcpy(out, k_thresh, sizeof(k_thresh));
}
```

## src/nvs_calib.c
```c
// nvs_calib.c
// Implementation for NVS calibration storage for gesture thresholds

#include <zephyr/storage/flash_map.h>
#include <zephyr/fs/nvs.h>
#include <zephyr/kernel.h>
#include <string.h>
#include "nvs_calib.h"

#define NVS_PARTITION storage
#define NVS_CALIB_ID 0x100

static struct nvs_fs fs;
static bool nvs_ready = false;

static uint32_t crc32(const void *data, size_t len) {
    // Simple CRC32 (placeholder, use Zephyr's real implementation if available)
    const uint8_t *p = (const uint8_t *)data;
    uint32_t crc = 0xFFFFFFFF;
    for (size_t i = 0; i < len; i++) {
        crc ^= p[i];
        for (int j = 0; j < 8; j++)
            crc = (crc >> 1) ^ (0xEDB88320 & (-(crc & 1)));
    }
    return ~crc;
}

static void nvs_calib_init(void) {
    if (nvs_ready) return;
    fs.offset = FLASH_AREA_OFFSET(NVS_PARTITION);
    fs.sector_size = FLASH_AREA_SIZE(NVS_PARTITION);
    fs.sector_count = 1;
    nvs_mount(&fs);
    nvs_ready = true;
}

bool nvs_calib_save(const nvs_calib_data_t *data) {
    nvs_calib_init();
    nvs_calib_data_t tmp = *data;
    tmp.crc = crc32(tmp.fist_adc, sizeof(tmp.fist_adc));
    int rc = nvs_write(&fs, NVS_CALIB_ID, &tmp, sizeof(tmp));
    return rc == sizeof(tmp);
}

bool nvs_calib_load(nvs_calib_data_t *data) {
    nvs_calib_init();
    int rc = nvs_read(&fs, NVS_CALIB_ID, data, sizeof(*data));
    if (rc != sizeof(*data)) return false;
    uint32_t crc = crc32(data->fist_adc, sizeof(data->fist_adc));
    return (crc == data->crc);
}

bool nvs_calib_exists(void) {
    nvs_calib_data_t tmp;
    return nvs_calib_load(&tmp);
}
```

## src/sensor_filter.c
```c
/**
 * @file sensor_filter.c
 * @brief Moving average filter for flex sensor data (ESP32 brain)
 */

#include <zephyr/kernel.h>
#include <zephyr/logging/log.h>
#include <string.h>

#include "app_config.h"
#include "common_types.h"
#include "sensor_filter.h"

LOG_MODULE_REGISTER(sensor_filter, CONFIG_LOG_DEFAULT_LEVEL);

/* ---------- Filter state (moved from STM32) ---------- */
static uint16_t filter_buf[NUM_FLEX_SENSORS][FILTER_WINDOW_SIZE];
static uint8_t  filter_idx[NUM_FLEX_SENSORS];
static uint32_t filter_sum[NUM_FLEX_SENSORS];
static bool     initialized = false;

int sensor_filter_init(void)
{
    if (initialized) {
        LOG_WRN("sensor_filter already initialized");
        return 0;
    }

    (void)memset(filter_buf, 0, sizeof(filter_buf));
    (void)memset(filter_idx, 0, sizeof(filter_idx));
    (void)memset(filter_sum, 0, sizeof(filter_sum));

    initialized = true;
    LOG_INF("Sensor filter initialized (window size: %u)", FILTER_WINDOW_SIZE);
    return 0;
}

uint16_t sensor_filter_update(uint8_t channel, uint16_t raw_value)
{
    if (!initialized) {
        LOG_ERR("Filter not initialized");
        return raw_value;
    }

    if (channel >= (uint8_t)NUM_FLEX_SENSORS) {
        LOG_ERR("Invalid channel: %u", channel);
        return raw_value;
    }

    /* Clamp to valid ADC range */
    if (raw_value > (uint16_t)ADC_MAX_VALID) {
        raw_value = (uint16_t)ADC_MAX_VALID;
    }

    /* Update moving average */
    uint8_t idx = filter_idx[channel];
    filter_sum[channel] -= filter_buf[channel][idx];
    filter_buf[channel][idx] = raw_value;
    filter_sum[channel] += raw_value;
    filter_idx[channel] = (uint8_t)((idx + 1U) % FILTER_WINDOW_SIZE);

    return (uint16_t)(filter_sum[channel] / FILTER_WINDOW_SIZE);
}

uint16_t sensor_filter_get(uint8_t channel)
{
    if (!initialized || channel >= (uint8_t)NUM_FLEX_SENSORS) {
        return 0U;
    }

    return (uint16_t)(filter_sum[channel] / FILTER_WINDOW_SIZE);
}

void sensor_filter_get_all(uint16_t out[NUM_FLEX_SENSORS])
{
    if (!initialized || out == NULL) {
        return;
    }

    for (uint8_t i = 0U; i < (uint8_t)NUM_FLEX_SENSORS; i++) {
        out[i] = (uint16_t)(filter_sum[i] / FILTER_WINDOW_SIZE);
    }
}

void sensor_filter_reset(void)
{
    if (!initialized) {
        return;
    }

    LOG_INF("Resetting filter state");
    (void)memset(filter_buf, 0, sizeof(filter_buf));
    (void)memset(filter_idx, 0, sizeof(filter_idx));
    (void)memset(filter_sum, 0, sizeof(filter_sum));
}

uint8_t sensor_filter_get_window_size(void)
{
    return (uint8_t)FILTER_WINDOW_SIZE;
}
```
